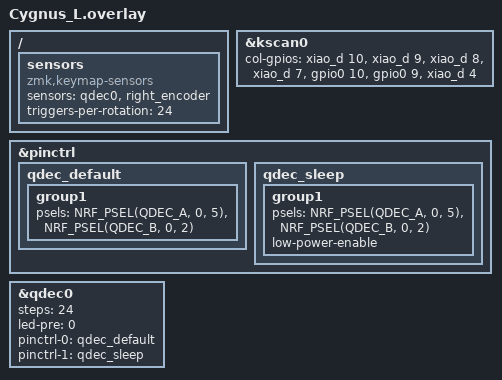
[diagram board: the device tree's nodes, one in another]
#include "Cygnus.dtsi"

&kscan0 {
        col-gpios
            = <&xiao_d 10 GPIO_ACTIVE_HIGH>
            , <&xiao_d 9 GPIO_ACTIVE_HIGH>
            , <&xiao_d 8 GPIO_ACTIVE_HIGH>
            , <&xiao_d 7 GPIO_ACTIVE_HIGH>
            , <&gpio0 10 GPIO_ACTIVE_HIGH>
            , <&gpio0 9 GPIO_ACTIVE_HIGH>
            , <&xiao_d 4 GPIO_ACTIVE_HIGH>
            ;
};

/ {
    sensors: sensors {
        compatible = "zmk,keymap-sensors";
        sensors = <&qdec0 &right_encoder>;
        triggers-per-rotation = <24>;
    };
};

&pinctrl {
    qdec_default: qdec_default {
        group1 {
            psels = <NRF_PSEL(QDEC_A, 0, 5)>,
                    <NRF_PSEL(QDEC_B, 0, 2)>;
        };
    };

    qdec_sleep: qdec_sleep {
        group1 {
            psels = <NRF_PSEL(QDEC_A, 0, 5)>,
                    <NRF_PSEL(QDEC_B, 0, 2)>;
            low-power-enable;
        };
    };
};

&qdec0 {
    status = "okay";
    steps = <24>;
    led-pre = <0>;
    pinctrl-0 = <&qdec_default>;
    pinctrl-1 = <&qdec_sleep>;
    pinctrl-names = "default", "sleep";
};
